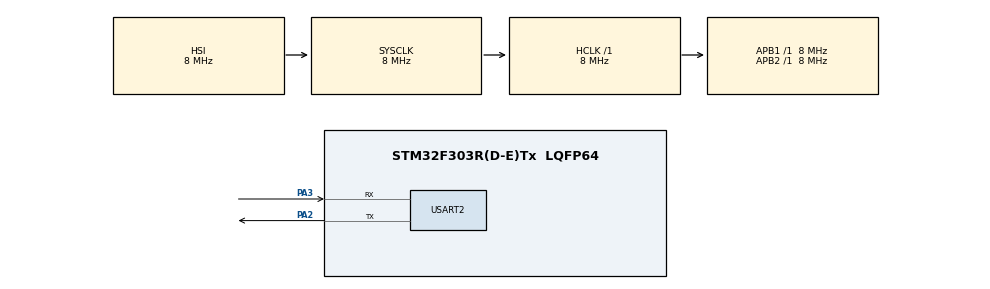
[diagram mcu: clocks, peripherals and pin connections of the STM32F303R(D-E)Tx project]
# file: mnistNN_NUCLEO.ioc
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Dma.Request0=USART2_RX
Dma.Request1=USART2_TX
Dma.USART2_RX.0.Direction=DMA_PERIPH_TO_MEMORY
Dma.USART2_RX.0.Instance=DMA1_Channel6
Dma.USART2_RX.0.MemDataAlignment=DMA_MDATAALIGN_BYTE
Dma.USART2_RX.0.MemInc=DMA_MINC_ENABLE
Dma.USART2_RX.0.Mode=DMA_NORMAL
Dma.USART2_RX.0.PeriphDataAlignment=DMA_PDATAALIGN_BYTE
Dma.USART2_RX.0.PeriphInc=DMA_PINC_DISABLE
Dma.USART2_RX.0.Priority=DMA_PRIORITY_LOW
Dma.USART2_TX.1.Direction=DMA_MEMORY_TO_PERIPH
Dma.USART2_TX.1.Instance=DMA1_Channel7
Dma.USART2_TX.1.MemDataAlignment=DMA_MDATAALIGN_BYTE
Dma.USART2_TX.1.MemInc=DMA_MINC_ENABLE
Dma.USART2_TX.1.Mode=DMA_NORMAL
Dma.USART2_TX.1.PeriphDataAlignment=DMA_PDATAALIGN_BYTE
Dma.USART2_TX.1.PeriphInc=DMA_PINC_DISABLE
Dma.USART2_TX.1.Priority=DMA_PRIORITY_LOW
Mcu.Family=STM32F3
Mcu.Name=STM32F303R(D-E)Tx
Mcu.Package=LQFP64
NVIC.DMA1_Channel6_IRQn=true\:0\:0\:false\:false\:true\:false\:true\:true
NVIC.DMA1_Channel7_IRQn=true\:0\:0\:false\:false\:true\:false\:true\:true
NVIC.PriorityGroup=NVIC_PRIORITYGROUP_4
PA2.Mode=Asynchronous
PA2.Signal=USART2_TX
PA3.Mode=Asynchronous
PA3.Signal=USART2_RX
ProjectManager.HeapSize=0x200
ProjectManager.StackSize=0x400
ProjectManager.TargetToolchain=STM32CubeIDE
RCC.AHBFreq_Value=8000000
RCC.APB1Freq_Value=8000000
RCC.APB2Freq_Value=8000000
RCC.CortexFreq_Value=8000000
RCC.HSE_VALUE=8000000
RCC.HSI_VALUE=8000000
RCC.LSE_VALUE=32768
RCC.SYSCLKFreq_VALUE=8000000
RCC.USBFreq_Value=16000000
USART2.VirtualMode-Asynchronous=VM_ASYNC
board=custom

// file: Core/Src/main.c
/* USER CODE BEGIN Header */
/**
  ******************************************************************************
  * @file           : main.c
  * @brief          : Main program body
  ******************************************************************************
  * @attention
  *
  * Copyright (c) 2024 STMicroelectronics.
  * All rights reserved.
  *
  * This software is licensed under terms that can be found in the LICENSE file
  * in the root directory of this software component.
  * If no LICENSE file comes with this software, it is provided AS-IS.
  *
  ******************************************************************************
  */
/* USER CODE END Header */
#include "main.h"
#include "weights.h"
#include <math.h>
#include <stdint.h>
#include <stdbool.h>

UART_HandleTypeDef huart2;
DMA_HandleTypeDef hdma_usart2_rx;
DMA_HandleTypeDef hdma_usart2_tx;

void SystemClock_Config(void);
static void MX_GPIO_Init(void);
static void MX_DMA_Init(void);
static void MX_USART2_UART_Init(void);

/* USER CODE BEGIN 0 */
void relu(float *input, int size);
void softmax(float *input, int size);

void dense_layer(const float* input, const float* weights, const float* biases, float* output, uint32_t input_size, uint32_t nodes);

void forward_pass(const float *input, float *output, int input_size, int hidden_size, int output_size);

float rx_buffer[784];
float tx_buffer[10];

float dense_1_output[20];
float dense_2_output[10];

bool data_ready = false;
/* USER CODE END 0 */

int main(void)
{

  /* MCU Configuration--------------------------------------------------------*/

  /* Reset of all peripherals, Initializes the Flash interface and the Systick. */
  HAL_Init();

  /* Configure the system clock */
  SystemClock_Config();

  /* Initialize all configured peripherals */
  MX_GPIO_Init();
  MX_DMA_Init();
  MX_USART2_UART_Init();

  /* Infinite loop */
  while (1)
  {
	  if (data_ready){
		forward_pass(rx_buffer, tx_buffer, 784, 20, 10);
		HAL_UART_Transmit(&huart2 ,tx_buffer, (sizeof(tx_buffer)*4), HAL_MAX_DELAY);
		data_ready = false;
	  }
	  else{
		  HAL_UART_Receive_DMA(&huart2, (uint8_t*)rx_buffer, sizeof(rx_buffer));;
	  }

  }
}

void SystemClock_Config(void)
{
  RCC_OscInitTypeDef RCC_OscInitStruct = {0};
  RCC_ClkInitTypeDef RCC_ClkInitStruct = {0};
  RCC_PeriphCLKInitTypeDef PeriphClkInit = {0};

  /** Initializes the RCC Oscillators according to the specified parameters
  * in the RCC_OscInitTypeDef structure.
  */
  RCC_OscInitStruct.OscillatorType = RCC_OSCILLATORTYPE_HSI;
  RCC_OscInitStruct.HSIState = RCC_HSI_ON;
  RCC_OscInitStruct.HSICalibrationValue = RCC_HSICALIBRATION_DEFAULT;
  RCC_OscInitStruct.PLL.PLLState = RCC_PLL_NONE;
  if (HAL_RCC_OscConfig(&RCC_OscInitStruct) != HAL_OK)
  {
    Error_Handler();
  }

  /** Initializes the CPU, AHB and APB buses clocks
  */
  RCC_ClkInitStruct.ClockType = RCC_CLOCKTYPE_HCLK|RCC_CLOCKTYPE_SYSCLK
                              |RCC_CLOCKTYPE_PCLK1|RCC_CLOCKTYPE_PCLK2;
  RCC_ClkInitStruct.SYSCLKSource = RCC_SYSCLKSOURCE_HSI;
  RCC_ClkInitStruct.AHBCLKDivider = RCC_SYSCLK_DIV1;
  RCC_ClkInitStruct.APB1CLKDivider = RCC_HCLK_DIV1;
  RCC_ClkInitStruct.APB2CLKDivider = RCC_HCLK_DIV1;

  if (HAL_RCC_ClockConfig(&RCC_ClkInitStruct, FLASH_LATENCY_0) != HAL_OK)
  {
    Error_Handler();
  }
  PeriphClkInit.PeriphClockSelection = RCC_PERIPHCLK_USART2;
  PeriphClkInit.Usart2ClockSelection = RCC_USART2CLKSOURCE_PCLK1;
  if (HAL_RCCEx_PeriphCLKConfig(&PeriphClkInit) != HAL_OK)
  {
    Error_Handler();
  }
}

static void MX_USART2_UART_Init(void)
{

  huart2.Instance = USART2;
  huart2.Init.BaudRate = 38400;
  huart2.Init.WordLength = UART_WORDLENGTH_8B;
  huart2.Init.StopBits = UART_STOPBITS_1;
  huart2.Init.Parity = UART_PARITY_NONE;
  huart2.Init.Mode = UART_MODE_TX_RX;
  huart2.Init.HwFlowCtl = UART_HWCONTROL_NONE;
  huart2.Init.OverSampling = UART_OVERSAMPLING_16;
  huart2.Init.OneBitSampling = UART_ONE_BIT_SAMPLE_DISABLE;
  huart2.AdvancedInit.AdvFeatureInit = UART_ADVFEATURE_NO_INIT;
  if (HAL_UART_Init(&huart2) != HAL_OK)
  {
    Error_Handler();
  }

}

static void MX_DMA_Init(void)
{

  /* DMA controller clock enable */
  __HAL_RCC_DMA1_CLK_ENABLE();

  /* DMA interrupt init */
  /* DMA1_Channel6_IRQn interrupt configuration */
  HAL_NVIC_SetPriority(DMA1_Channel6_IRQn, 0, 0);
  HAL_NVIC_EnableIRQ(DMA1_Channel6_IRQn);
  /* DMA1_Channel7_IRQn interrupt configuration */
  HAL_NVIC_SetPriority(DMA1_Channel7_IRQn, 0, 0);
  HAL_NVIC_EnableIRQ(DMA1_Channel7_IRQn);

}

static void MX_GPIO_Init(void)
{

  /* GPIO Ports Clock Enable */
  __HAL_RCC_GPIOA_CLK_ENABLE();

}

/* USER CODE BEGIN 4 */
//ReLu activation function
void relu(float *input, int size) {
    for (int i = 0; i < size; i++) {
        if (input[i] < 0) {
            input[i] = 0;
        }
    }
}

//Softmax activation function
void softmax(float *input, int size) {
    float max_val = input[0];
    for (int i = 1; i < size; i++) {
        if (input[i] > max_val) {
            max_val = input[i];
        }
    }

    float sum_exp = 0.0;
    for (int i = 0; i < size; i++) {
        input[i] = expf(input[i] - max_val);
        sum_exp += input[i];
    }

    for (int i = 0; i < size; i++) {
        input[i] /= sum_exp;
    }
}

// Forward pass function
void forward_pass(const float *input, float *output, int input_size, int hidden_size, int output_size) {
    // Define the layer outputs
    float hidden_layer_output[hidden_size];

    // First Dense Layer
    dense_layer(input, layers_dense_vars_0, layers_dense_vars_1, hidden_layer_output, input_size, hidden_size);
    relu(hidden_layer_output, hidden_size);

    // Second Dense Layer
    dense_layer(hidden_layer_output, layers_dense_vars_0, layers_dense_vars_1, output, hidden_size, output_size);

    // Apply softmax to the output layer
    softmax(output, output_size);
}

// Dense Layer
void dense_layer(const float* input, const float* weights, const float* biases, float* output, uint32_t input_size, uint32_t nodes) {
    for (uint32_t i = 0; i < nodes; i++) {
        output[i] = biases[i]; // Initialize output with the bias
        for (uint32_t j = 0; j < input_size; j++) {
            output[i] += input[j] * weights[j * nodes + i];
        }
    }
}

void HAL_UART_RxCpltCallback(UART_HandleTypeDef *huart){
	if (huart->Instance == USART2)
	  {
		data_ready = true;
	  }
}
/* USER CODE END 4 */

void Error_Handler(void)
{
  __disable_irq();
  while (1)
  {
  }
}
